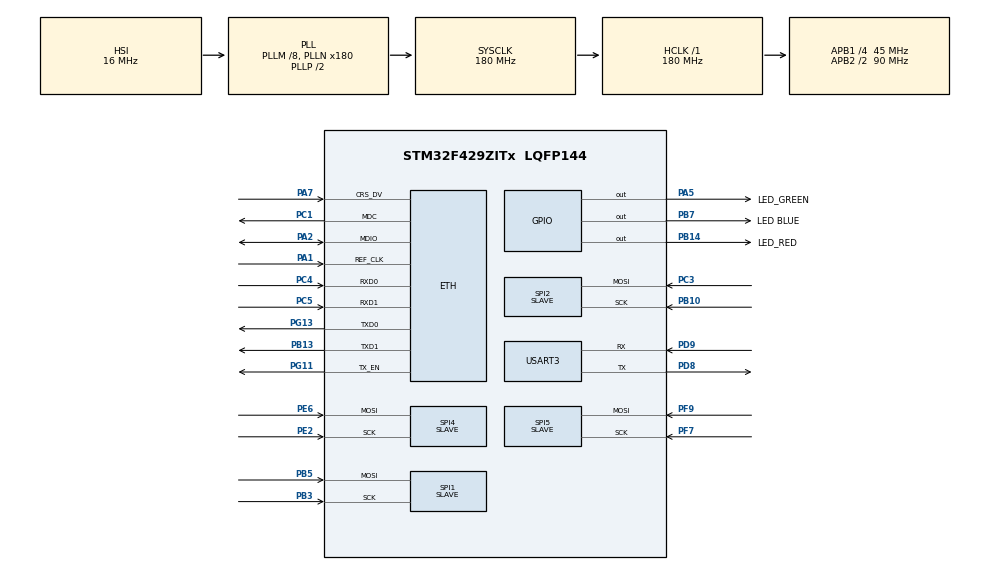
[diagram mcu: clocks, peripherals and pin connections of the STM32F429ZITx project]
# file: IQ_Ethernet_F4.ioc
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Mcu.Family=STM32F4
PC3.Mode=RX_Only_Simplex_Unidirect_Slave
RCC.CortexFreq_Value=180000000
SPI4.VirtualType=VM_SLAVE
SPI1.VirtualType=VM_SLAVE
SPI2.VirtualType=VM_SLAVE
PB10.Mode=RX_Only_Simplex_Unidirect_Slave
PB14.GPIO_Label=LED_RED
SPI4.Direction=SPI_DIRECTION_2LINES_RXONLY
SPI5.CLKPhase=SPI_PHASE_2EDGE
PC5.Mode=RMII
PB13.Signal=ETH_TXD1
PG13.Signal=ETH_TXD0
PD9.Mode=Asynchronous
PG11.Signal=ETH_TX_EN
RCC.SYSCLKSource=RCC_SYSCLKSOURCE_PLLCLK
ProjectManager.StackSize=0x400
LWIP.NETMASK_ADDRESS=255.255.255.000
SPI4.Mode=SPI_MODE_SLAVE
PF7.Signal=SPI5_SCK
SPI1.Direction=SPI_DIRECTION_2LINES_RXONLY
RCC.HCLKFreq_Value=180000000
PE2.Mode=RX_Only_Simplex_Unidirect_Slave
RCC.APB2TimFreq_Value=180000000
PC3.Signal=SPI2_MOSI
PD8.Signal=USART3_TX
RCC.AHBFreq_Value=180000000
RCC.HSE_VALUE=25000000
PB3.Mode=RX_Only_Simplex_Unidirect_Slave
PF9.Mode=RX_Only_Simplex_Unidirect_Slave
LWIP.MEM_SIZE=10*1024
PB5.Mode=RX_Only_Simplex_Unidirect_Slave
PE2.Signal=SPI4_SCK
PB7.Signal=GPIO_Output
PG13.Mode=RMII
TIM6.Period=11250
PB7.GPIO_Label=LED BLUE
Mcu.Package=LQFP144
SPI2.Mode=SPI_MODE_SLAVE
RCC.APB2CLKDivider=RCC_HCLK_DIV2
RCC.APB1TimFreq_Value=90000000
SPI2.Direction=SPI_DIRECTION_2LINES_RXONLY
PC5.Signal=ETH_RXD1
PB13.Mode=RMII
SPI5.VirtualType=VM_SLAVE
PC4.Mode=RMII
LWIP.IP_ADDRESS=192.168.001.195
PA7.Mode=RMII
TIM6.Prescaler=90
PC4.Signal=ETH_RXD0
VP_TIM6_VS_ClockSourceINT.Mode=Enable_Timer
PD9.Signal=USART3_RX
LWIP.LWIP_DHCP=0
RCC.APB1CLKDivider=RCC_HCLK_DIV4
ETH.PhyAddress=0
SPI5.Mode=SPI_MODE_SLAVE
VP_LWIP_VS_Enabled.Mode=Enabled
LWIP.GATEWAY_ADDRESS=192.168.001.254
PF7.Mode=RX_Only_Simplex_Unidirect_Slave
TIM6.AutoReloadPreload=TIM_AUTORELOAD_PRELOAD_ENABLE
ProjectManager.TargetToolchain=STM32CubeIDE
RCC.LSE_VALUE=32768
PD8.Mode=Asynchronous
PA1.Signal=ETH_REF_CLK
PB10.Signal=SPI2_SCK
PB14.Signal=GPIO_Output
PA5.Signal=GPIO_Output
board=custom
RCC.VCOOutputFreq_Value=360000000
RCC.APB2Freq_Value=90000000
PA1.Mode=RMII
PE6.Mode=RX_Only_Simplex_Unidirect_Slave
SPI1.Mode=SPI_MODE_SLAVE
PE6.Signal=SPI4_MOSI
Mcu.Name=STM32F429ZITx
PA2.Signal=ETH_MDIO
RCC.48MHZClocksFreq_Value=90000000
PB3.Signal=SPI1_SCK
RCC.SYSCLKFreq_VALUE=180000000
PB5.Signal=SPI1_MOSI
ETH.MediaInterface=ETH_MEDIA_INTERFACE_RMII
PA5.GPIO_Label=LED_GREEN
USART3.VirtualMode=VM_ASYNC
PG11.Mode=RMII
ProjectManager.HeapSize=0x200
LWIP.Version=v2.1.2_Cube
PF9.Signal=SPI5_MOSI
RCC.HSI_VALUE=16000000
NVIC.PriorityGroup=NVIC_PRIORITYGROUP_4
RCC.PLLM=8
RCC.PLLN=180
PA2.Mode=RMII
RCC.APB1Freq_Value=45000000
PC1.Signal=ETH_MDC
PC1.Mode=RMII
SPI5.Direction=SPI_DIRECTION_2LINES_RXONLY
PA7.Signal=ETH_CRS_DV

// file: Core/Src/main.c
/* USER CODE BEGIN Header */
/**
  ******************************************************************************
  * @file           : main.c
  * @brief          : Main program body
  ******************************************************************************
  * @attention
  *
  * <h2><center>&copy; Copyright (c) 2022 STMicroelectronics.
  * All rights reserved.</center></h2>
  *
  * This software component is licensed by ST under BSD 3-Clause license,
  * the "License"; You may not use this file except in compliance with the
  * License. You may obtain a copy of the License at:
  *                        opensource.org/licenses/BSD-3-Clause
  *
  ******************************************************************************
  */
/* USER CODE END Header */
#include <app_main.h>
#include "main.h"
#include "lwip.h"

SPI_HandleTypeDef hspi1;
SPI_HandleTypeDef hspi2;
SPI_HandleTypeDef hspi4;
SPI_HandleTypeDef hspi5;

TIM_HandleTypeDef htim6;

UART_HandleTypeDef huart3;

void SystemClock_Config(void);
static void MX_GPIO_Init(void);
static void MX_SPI1_Init(void);
static void MX_SPI2_Init(void);
static void MX_SPI4_Init(void);
static void MX_USART3_UART_Init(void);
static void MX_TIM6_Init(void);
static void MX_SPI5_Init(void);

int main(void)
{

  /* MCU Configuration--------------------------------------------------------*/

  /* Reset of all peripherals, Initializes the Flash interface and the Systick. */
  HAL_Init();

  /* Configure the system clock */
  SystemClock_Config();

  /* Initialize all configured peripherals */
  MX_GPIO_Init();
  MX_LWIP_Init();
  MX_SPI1_Init();
  MX_SPI2_Init();
  MX_SPI4_Init();
  MX_USART3_UART_Init();
  MX_TIM6_Init();
  MX_SPI5_Init();
  /* USER CODE BEGIN 2 */
  uint8_t pData[] = "HELLO";
  HAL_UART_Transmit(&huart3, pData, 5, 100);

  App_Init();
  //App_Testing();
  App_Runtime();
  /* USER CODE END 2 */

  /* Infinite loop */
  while (1)
  {

  }
}

void SystemClock_Config(void)
{
  RCC_OscInitTypeDef RCC_OscInitStruct = {0};
  RCC_ClkInitTypeDef RCC_ClkInitStruct = {0};

  /** Configure the main internal regulator output voltage
  */
  __HAL_RCC_PWR_CLK_ENABLE();
  __HAL_PWR_VOLTAGESCALING_CONFIG(PWR_REGULATOR_VOLTAGE_SCALE1);
  /** Initializes the RCC Oscillators according to the specified parameters
  * in the RCC_OscInitTypeDef structure.
  */
  RCC_OscInitStruct.OscillatorType = RCC_OSCILLATORTYPE_HSI;
  RCC_OscInitStruct.HSIState = RCC_HSI_ON;
  RCC_OscInitStruct.HSICalibrationValue = RCC_HSICALIBRATION_DEFAULT;
  RCC_OscInitStruct.PLL.PLLState = RCC_PLL_ON;
  RCC_OscInitStruct.PLL.PLLSource = RCC_PLLSOURCE_HSI;
  RCC_OscInitStruct.PLL.PLLM = 8;
  RCC_OscInitStruct.PLL.PLLN = 180;
  RCC_OscInitStruct.PLL.PLLP = RCC_PLLP_DIV2;
  RCC_OscInitStruct.PLL.PLLQ = 4;
  if (HAL_RCC_OscConfig(&RCC_OscInitStruct) != HAL_OK)
  {
    Error_Handler();
  }
  /** Activate the Over-Drive mode
  */
  if (HAL_PWREx_EnableOverDrive() != HAL_OK)
  {
    Error_Handler();
  }
  /** Initializes the CPU, AHB and APB buses clocks
  */
  RCC_ClkInitStruct.ClockType = RCC_CLOCKTYPE_HCLK|RCC_CLOCKTYPE_SYSCLK
                              |RCC_CLOCKTYPE_PCLK1|RCC_CLOCKTYPE_PCLK2;
  RCC_ClkInitStruct.SYSCLKSource = RCC_SYSCLKSOURCE_PLLCLK;
  RCC_ClkInitStruct.AHBCLKDivider = RCC_SYSCLK_DIV1;
  RCC_ClkInitStruct.APB1CLKDivider = RCC_HCLK_DIV4;
  RCC_ClkInitStruct.APB2CLKDivider = RCC_HCLK_DIV2;

  if (HAL_RCC_ClockConfig(&RCC_ClkInitStruct, FLASH_LATENCY_5) != HAL_OK)
  {
    Error_Handler();
  }
}

static void MX_SPI1_Init(void)
{

  /* SPI1 parameter configuration*/
  hspi1.Instance = SPI1;
  hspi1.Init.Mode = SPI_MODE_SLAVE;
  hspi1.Init.Direction = SPI_DIRECTION_2LINES_RXONLY;
  hspi1.Init.DataSize = SPI_DATASIZE_8BIT;
  hspi1.Init.CLKPolarity = SPI_POLARITY_LOW;
  hspi1.Init.CLKPhase = SPI_PHASE_1EDGE;
  hspi1.Init.NSS = SPI_NSS_SOFT;
  hspi1.Init.FirstBit = SPI_FIRSTBIT_MSB;
  hspi1.Init.TIMode = SPI_TIMODE_DISABLE;
  hspi1.Init.CRCCalculation = SPI_CRCCALCULATION_DISABLE;
  hspi1.Init.CRCPolynomial = 10;
  if (HAL_SPI_Init(&hspi1) != HAL_OK)
  {
    Error_Handler();
  }

}

static void MX_SPI2_Init(void)
{

  /* SPI2 parameter configuration*/
  hspi2.Instance = SPI2;
  hspi2.Init.Mode = SPI_MODE_SLAVE;
  hspi2.Init.Direction = SPI_DIRECTION_2LINES_RXONLY;
  hspi2.Init.DataSize = SPI_DATASIZE_8BIT;
  hspi2.Init.CLKPolarity = SPI_POLARITY_LOW;
  hspi2.Init.CLKPhase = SPI_PHASE_1EDGE;
  hspi2.Init.NSS = SPI_NSS_SOFT;
  hspi2.Init.FirstBit = SPI_FIRSTBIT_MSB;
  hspi2.Init.TIMode = SPI_TIMODE_DISABLE;
  hspi2.Init.CRCCalculation = SPI_CRCCALCULATION_DISABLE;
  hspi2.Init.CRCPolynomial = 10;
  if (HAL_SPI_Init(&hspi2) != HAL_OK)
  {
    Error_Handler();
  }

}

static void MX_SPI4_Init(void)
{

  /* SPI4 parameter configuration*/
  hspi4.Instance = SPI4;
  hspi4.Init.Mode = SPI_MODE_SLAVE;
  hspi4.Init.Direction = SPI_DIRECTION_2LINES_RXONLY;
  hspi4.Init.DataSize = SPI_DATASIZE_8BIT;
  hspi4.Init.CLKPolarity = SPI_POLARITY_LOW;
  hspi4.Init.CLKPhase = SPI_PHASE_1EDGE;
  hspi4.Init.NSS = SPI_NSS_SOFT;
  hspi4.Init.FirstBit = SPI_FIRSTBIT_MSB;
  hspi4.Init.TIMode = SPI_TIMODE_DISABLE;
  hspi4.Init.CRCCalculation = SPI_CRCCALCULATION_DISABLE;
  hspi4.Init.CRCPolynomial = 10;
  if (HAL_SPI_Init(&hspi4) != HAL_OK)
  {
    Error_Handler();
  }

}

static void MX_SPI5_Init(void)
{

  /* SPI5 parameter configuration*/
  hspi5.Instance = SPI5;
  hspi5.Init.Mode = SPI_MODE_SLAVE;
  hspi5.Init.Direction = SPI_DIRECTION_2LINES_RXONLY;
  hspi5.Init.DataSize = SPI_DATASIZE_8BIT;
  hspi5.Init.CLKPolarity = SPI_POLARITY_LOW;
  hspi5.Init.CLKPhase = SPI_PHASE_2EDGE;
  hspi5.Init.NSS = SPI_NSS_SOFT;
  hspi5.Init.FirstBit = SPI_FIRSTBIT_MSB;
  hspi5.Init.TIMode = SPI_TIMODE_DISABLE;
  hspi5.Init.CRCCalculation = SPI_CRCCALCULATION_DISABLE;
  hspi5.Init.CRCPolynomial = 10;
  if (HAL_SPI_Init(&hspi5) != HAL_OK)
  {
    Error_Handler();
  }

}

static void MX_TIM6_Init(void)
{

  TIM_MasterConfigTypeDef sMasterConfig = {0};

  htim6.Instance = TIM6;
  htim6.Init.Prescaler = 90;
  htim6.Init.CounterMode = TIM_COUNTERMODE_UP;
  htim6.Init.Period = 11250;
  htim6.Init.AutoReloadPreload = TIM_AUTORELOAD_PRELOAD_ENABLE;
  if (HAL_TIM_Base_Init(&htim6) != HAL_OK)
  {
    Error_Handler();
  }
  sMasterConfig.MasterOutputTrigger = TIM_TRGO_RESET;
  sMasterConfig.MasterSlaveMode = TIM_MASTERSLAVEMODE_DISABLE;
  if (HAL_TIMEx_MasterConfigSynchronization(&htim6, &sMasterConfig) != HAL_OK)
  {
    Error_Handler();
  }

}

static void MX_USART3_UART_Init(void)
{

  huart3.Instance = USART3;
  huart3.Init.BaudRate = 115200;
  huart3.Init.WordLength = UART_WORDLENGTH_8B;
  huart3.Init.StopBits = UART_STOPBITS_1;
  huart3.Init.Parity = UART_PARITY_NONE;
  huart3.Init.Mode = UART_MODE_TX_RX;
  huart3.Init.HwFlowCtl = UART_HWCONTROL_NONE;
  huart3.Init.OverSampling = UART_OVERSAMPLING_16;
  if (HAL_UART_Init(&huart3) != HAL_OK)
  {
    Error_Handler();
  }

}

static void MX_GPIO_Init(void)
{
  GPIO_InitTypeDef GPIO_InitStruct = {0};

  /* GPIO Ports Clock Enable */
  __HAL_RCC_GPIOE_CLK_ENABLE();
  __HAL_RCC_GPIOF_CLK_ENABLE();
  __HAL_RCC_GPIOC_CLK_ENABLE();
  __HAL_RCC_GPIOA_CLK_ENABLE();
  __HAL_RCC_GPIOB_CLK_ENABLE();
  __HAL_RCC_GPIOD_CLK_ENABLE();
  __HAL_RCC_GPIOG_CLK_ENABLE();

  /*Configure GPIO pin Output Level */
  HAL_GPIO_WritePin(LED_GREEN_GPIO_Port, LED_GREEN_Pin, GPIO_PIN_RESET);

  /*Configure GPIO pin Output Level */
  HAL_GPIO_WritePin(GPIOB, LED_RED_Pin|LED_BLUE_Pin, GPIO_PIN_RESET);

  /*Configure GPIO pin : LED_GREEN_Pin */
  GPIO_InitStruct.Pin = LED_GREEN_Pin;
  GPIO_InitStruct.Mode = GPIO_MODE_OUTPUT_PP;
  GPIO_InitStruct.Pull = GPIO_NOPULL;
  GPIO_InitStruct.Speed = GPIO_SPEED_FREQ_LOW;
  HAL_GPIO_Init(LED_GREEN_GPIO_Port, &GPIO_InitStruct);

  /*Configure GPIO pins : LED_RED_Pin LED_BLUE_Pin */
  GPIO_InitStruct.Pin = LED_RED_Pin|LED_BLUE_Pin;
  GPIO_InitStruct.Mode = GPIO_MODE_OUTPUT_PP;
  GPIO_InitStruct.Pull = GPIO_NOPULL;
  GPIO_InitStruct.Speed = GPIO_SPEED_FREQ_LOW;
  HAL_GPIO_Init(GPIOB, &GPIO_InitStruct);

}

void Error_Handler(void)
{
  __disable_irq();
  while (1)
  {
  }
}

/************************ (C) COPYRIGHT STMicroelectronics *****END OF FILE****/
